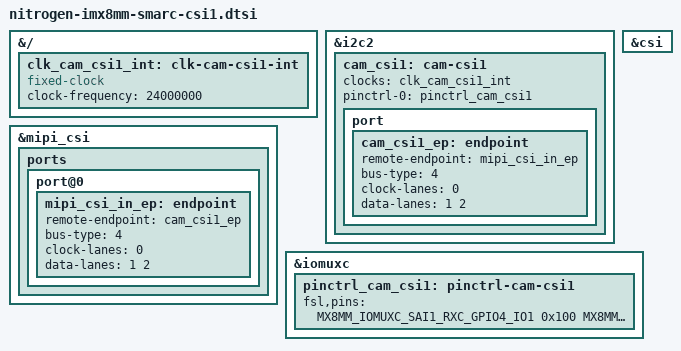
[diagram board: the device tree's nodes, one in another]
// SPDX-License-Identifier: (GPL-2.0+ OR MIT)
/*
 * Copyright 2025 Ezurio LLC
 */

#include <dt-bindings/gpio/gpio.h>

#include "imx8mm-pinfunc.h"

&{/} {
	clk_cam_csi1_int: clk-cam-csi1-int {
		compatible = "fixed-clock";
		#clock-cells = <0>;
		clock-frequency = <24000000>;
	};
};

&i2c2 {
	status = "okay";

	#address-cells = <1>;
	#size-cells = <0>;

	cam_csi1: cam-csi1 {
		clocks = <&clk_cam_csi1_int>; /* On Camera module */
		clock-names = "xclk";

		pinctrl-names = "default";
		pinctrl-0 = <&pinctrl_cam_csi1>;

		port {
			cam_csi1_ep: endpoint {
				remote-endpoint = <&mipi_csi_in_ep>;
				bus-type = <4>;
				clock-lanes = <0>;
				data-lanes = <1 2>;
			};
		};
	};
};

&mipi_csi {
	status = "okay";

	ports {
		port@0 {
			mipi_csi_in_ep: endpoint {
				remote-endpoint = <&cam_csi1_ep>;
				bus-type = <4>;
				clock-lanes = <0>;
				data-lanes = <1 2>;
			};
		};
	};
};

&csi {
	status = "okay";
};

&iomuxc {
	pinctrl_cam_csi1: pinctrl-cam-csi1 {
		fsl,pins = <
			MX8MM_IOMUXC_SAI1_RXC_GPIO4_IO1   0x100
			MX8MM_IOMUXC_GPIO1_IO15_GPIO1_IO15   0x100
		>;
	};
};
